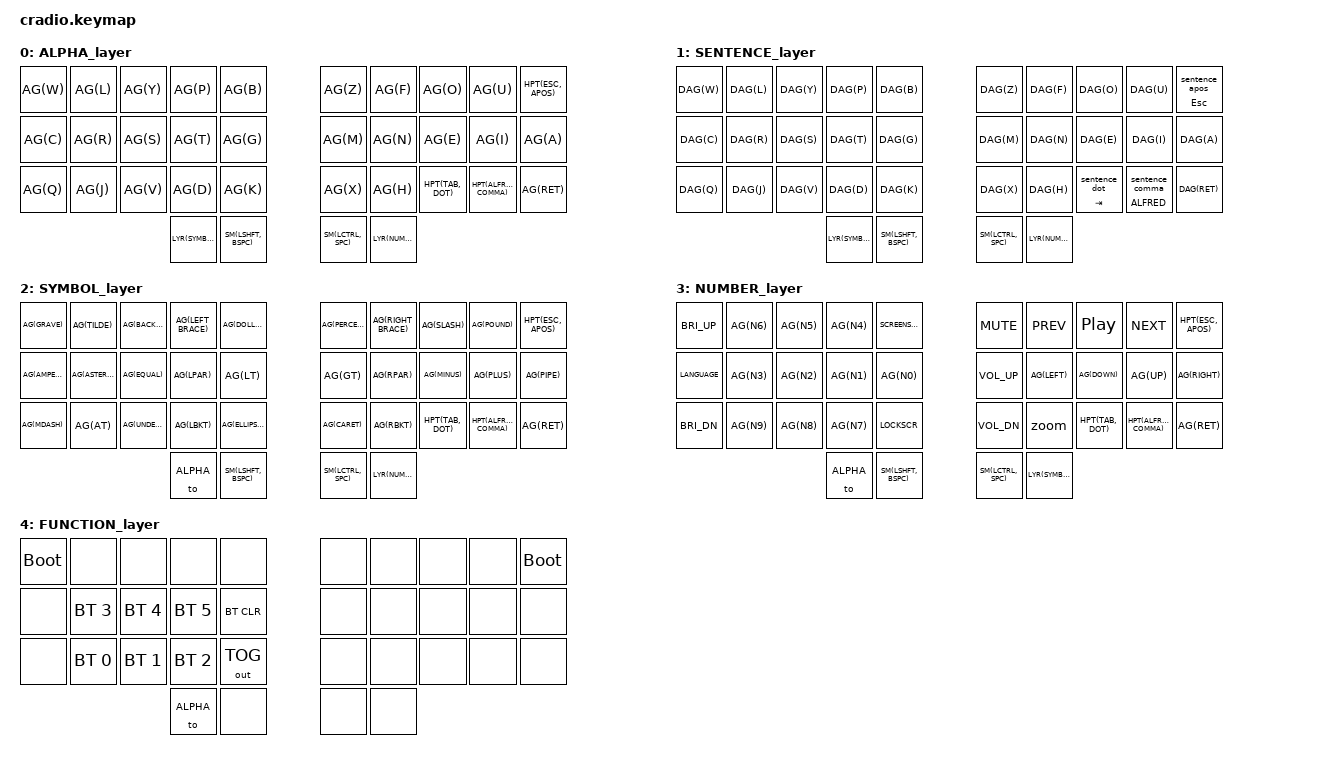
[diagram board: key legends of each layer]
/*
 * Copyright (c) 2020 The ZMK Contributors
 *
 * SPDX-License-Identifier: MIT
 */

#include <behaviors.dtsi>
#include <dt-bindings/zmk/keys.h>
#include <dt-bindings/zmk/bt.h>
#include <dt-bindings/zmk/outputs.h>

#define ALPHA 0
#define SENTENCE 1
#define SYMBOL 2
#define NUMBER 3
#define FUNCTION 4

#include "chords.keymap"

#define LANGUAGE LS(F1)
#define SCREENSHOT LG(LS(N4))
#define LOCKSCR LG(LC(Q))
#define ALFRED LG(SPC)
#define MDASH LA(LS(MINUS))
#define ELLIPSIS LA(SEMICOLON)

#define PHT(key1, key2) &prefer_hold_tap key1 key2
#define HPT(key1, key2) &hold_prefer_tap key1 key2
#define HTB(key1, key2) &balanced_hold_tap key1 key2
/ {
    behaviors {
        hold_prefer_tap: hold_prefer_tap {
            compatible = "zmk,behavior-hold-tap";
            label = "HOLD_PREFER_TAP";
            #binding-cells = <2>;
            tapping_term_ms = <200>;
            quick_tap_ms = <0>;
            flavor = "tap-preferred";
            bindings = <&kp>, <&kp>;
        };
        prefer_hold_tap: prefer_hold_tap {
            compatible = "zmk,behavior-hold-tap";
            label = "PREFER_HOLD_TAP";
            #binding-cells = <2>;
            tapping_term_ms = <200>;
            quick_tap_ms = <0>;
            flavor = "hold-preferred";
            bindings = <&kp>, <&kp>;
        };
        balanced_hold_tap: balanced_hold_tap {
            compatible = "zmk,behavior-hold-tap";
            label = "BALANCED_HOLD_TAP";
            #binding-cells = <2>;
            tapping_term_ms = <200>;
            quick_tap_ms = <0>;
            flavor = "balanced";
            bindings = <&kp>, <&kp>;
        };
    };
};

// Sticky mod on hold
#define SM(mod, keycode) &sm mod keycode
&sk {
    release-after-ms = <2000>;
    quick-release;
};
/ {
    behaviors {
        sm: sticky_mod {
            compatible = "zmk,behavior-hold-tap";
            label = "STICKY_MOD";
            #binding-cells = <2>;
            tapping_term_ms = <200>;
            quick_tap_ms = <0>;
            flavor = "hold-preferred";
            bindings = <&sk>, <&kp>;
        };
    };
};

// Like autoshift but for gui instead
#define AG(keycode) HPT(LG(keycode), keycode)

// Same, but dismisses sentence mode
#define str(s) #s
#define DISMISS_MACRO(key)                 \
macros {                                   \
  sentence_##key: sentence_##key {         \
    label = str(sentence_##key);           \
    compatible = "zmk,behavior-macro";     \
    #binding-cells = <0>;                  \
    tap-ms = <1>;                          \
    wait-ms = <1>;                         \
    bindings = <&to ALPHA &kp key>;        \
  };                                       \
  lg_sentence_##key: lg_sentence_##key {   \
    label = str(lg_sentence_##key);        \
    compatible = "zmk,behavior-macro";     \
    #binding-cells = <0>;                  \
    tap-ms = <1>;                          \
    wait-ms = <1>;                         \
    bindings = <&to ALPHA &kp LG(key)>;    \
  };                                       \
};                                         \
behaviors {                                \
  hold_prefer_##key: hold_prefer_##key {   \
    compatible = "zmk,behavior-hold-tap";  \
    label = str(hold_prefer_##key);        \
    #binding-cells = <2>;                  \
    tapping_term_ms = <200>;               \
    quick_tap_ms = <0>;                    \
    flavor = "tap-preferred";              \
    bindings = <&lg_sentence_##key>, <&sentence_##key>;  \
  };                                       \
};
/ {
  DISMISS_MACRO(A)
  DISMISS_MACRO(B)
  DISMISS_MACRO(C)
  DISMISS_MACRO(D)
  DISMISS_MACRO(E)
  DISMISS_MACRO(F)
  DISMISS_MACRO(G)
  DISMISS_MACRO(H)
  DISMISS_MACRO(I)
  DISMISS_MACRO(J)
  DISMISS_MACRO(K)
  DISMISS_MACRO(L)
  DISMISS_MACRO(M)
  DISMISS_MACRO(N)
  DISMISS_MACRO(O)
  DISMISS_MACRO(P)
  DISMISS_MACRO(Q)
  DISMISS_MACRO(R)
  DISMISS_MACRO(S)
  DISMISS_MACRO(T)
  DISMISS_MACRO(U)
  DISMISS_MACRO(V)
  DISMISS_MACRO(W)
  DISMISS_MACRO(X)
  DISMISS_MACRO(Y)
  DISMISS_MACRO(Z)
  DISMISS_MACRO(RET)
};
#define DAG(keycode) &hold_prefer_##keycode 0 0
/ {
  macros {
    sentence_dot: sentence_dot {
      label = "sentence_dot";
      compatible = "zmk,behavior-macro";
      #binding-cells = <0>;
      tap-ms = <1>;
      wait-ms = <1>;
      bindings = <&kp BSPC &kp DOT &kp SPC &sk LSHFT>;
    };
    sentence_comma: sentence_comma {
      label = "sentence_comma";
      compatible = "zmk,behavior-macro";
      #binding-cells = <0>;
      tap-ms = <1>;
      wait-ms = <1>;
      bindings = <&kp BSPC &kp COMMA &kp SPC>;
    };
    sentence_apos: sentence_apos {
      label = "sentence_apos";
      compatible = "zmk,behavior-macro";
      #binding-cells = <0>;
      tap-ms = <1>;
      wait-ms = <1>;
      bindings = <&kp BSPC &kp APOS>;
    };
  };
  behaviors {
    hold_prefer_dot: hold_prefer_dot {
      compatible = "zmk,behavior-hold-tap";
      label = "hold_prefer_dot";
      #binding-cells = <2>;
      tapping_term_ms = <200>;
      quick_tap_ms = <0>;
      flavor = "tap-preferred";
      bindings = <&kp>, <&sentence_dot>;
    };
    hold_prefer_comma: hold_prefer_comma {
      compatible = "zmk,behavior-hold-tap";
      label = "hold_prefer_comma";
      #binding-cells = <2>;
      tapping_term_ms = <200>;
      quick_tap_ms = <0>;
      flavor = "tap-preferred";
      bindings = <&kp>, <&sentence_comma>;
    };
    hold_prefer_apos: hold_prefer_apos {
      compatible = "zmk,behavior-hold-tap";
      label = "hold_prefer_apos";
      #binding-cells = <2>;
      tapping_term_ms = <200>;
      quick_tap_ms = <0>;
      flavor = "tap-preferred";
      bindings = <&kp>, <&sentence_apos>;
    };
  };
};

// chord spc + bkspc to delete a word, or hold for a hyper sticky modifier
#define HYPER LG(LA(LCTRL))
/ {
  combos {
    compatible = "zmk,combos";
    combo_del_word {
      timeout-ms = <60>;
      bindings = <SM(HYPER, LA(BSPC))>;
      key-positions = <31 32>;
    };
  };
};

// Chord left thumb keys as left click, right thumb keys as right click
// Hold for command versions
// TODO https://github.com/zmkfirmware/zmk/pull/1430
/ {
  combos {
    compatible = "zmk,combos";
    combo_left_click {
      timeout-ms = <60>;
      bindings = <HPT(&none, &none)>;
      key-positions = <30 31>;
    };
    combo_right_click {
      timeout-ms = <60>;
      bindings = <HPT(&none, &none)>;
      key-positions = <32 33>;
    };
  };
};

// Tap to toggle layer, chord to momentarily switch
#define LYR(layer) &mo_tog layer layer
/ {
  behaviors {
    mo_tog: behavior_mo_tog {
      compatible = "zmk,behavior-hold-tap";
      label = "mo_tog";
      #binding-cells = <2>;
      flavor = "hold-preferred";
      tapping-term-ms = <200>;
      bindings = <&mo>, <&tog>;
    };
  };
};

// Chord SYMBOL + NUMBER to get to FUNCTION layer
&sl {
    release-after-ms = <10000>;
};
/ {
  combos {
    compatible = "zmk,combos";
    combo_function_layer {
      timeout-ms = <60>;
      bindings = <&sl FUNCTION>;
      key-positions = <30 33>;
    };
  };
};

// Zoom in and out
/ {
  behaviors {
    zoom: zoom {
      compatible = "zmk,behavior-mod-morph";
      label = "ZOOM";
      #binding-cells = <0>;
      bindings = <&kp LG(PLUS)>, <&kp LG(MINUS)>;
      mods = <(MOD_LSFT|MOD_RSFT)>;
    };
  };
};

/ {
  keymap {
    compatible = "zmk,keymap";

    ALPHA_layer {
      bindings = <
        AG(W)  AG(L)  AG(Y)  AG(P)  AG(B)    AG(Z)  AG(F)  AG(O)          AG(U)               HPT(ESC, APOS)
        AG(C)  AG(R)  AG(S)  AG(T)  AG(G)    AG(M)  AG(N)  AG(E)          AG(I)               AG(A)
        AG(Q)  AG(J)  AG(V)  AG(D)  AG(K)    AG(X)  AG(H)  HPT(TAB, DOT)  HPT(ALFRED, COMMA)  AG(RET)
             LYR(SYMBOL)  SM(LSHFT, BSPC)    SM(LCTRL, SPC)  LYR(NUMBER)
      >;
    };

    SENTENCE_layer {
      bindings = <
        DAG(W)  DAG(L)  DAG(Y)  DAG(P)  DAG(B)    DAG(Z)  DAG(F)  DAG(O)                  DAG(U)                        &hold_prefer_apos ESC 0
        DAG(C)  DAG(R)  DAG(S)  DAG(T)  DAG(G)    DAG(M)  DAG(N)  DAG(E)                  DAG(I)                        DAG(A)
        DAG(Q)  DAG(J)  DAG(V)  DAG(D)  DAG(K)    DAG(X)  DAG(H)  &hold_prefer_dot TAB 0  &hold_prefer_comma ALFRED 0   DAG(RET)
                  LYR(SYMBOL)  SM(LSHFT, BSPC)    SM(LCTRL, SPC)  LYR(NUMBER)
      >;
    };

    SYMBOL_layer {
      bindings = <
        AG(GRAVE)      AG(TILDE)     AG(BACKSLASH)   AG(LEFT_BRACE)  AG(DOLLAR)      AG(PERCENT)  AG(RIGHT_BRACE)  AG(SLASH)      AG(POUND)           HPT(ESC, APOS)
        AG(AMPERSAND)  AG(ASTERISK)  AG(EQUAL)       AG(LPAR)        AG(LT)          AG(GT)       AG(RPAR)         AG(MINUS)      AG(PLUS)            AG(PIPE)
        AG(MDASH)      AG(AT)        AG(UNDERSCORE)  AG(LBKT)        AG(ELLIPSIS)    AG(CARET)    AG(RBKT)         HPT(TAB, DOT)  HPT(ALFRED, COMMA)  AG(RET)
                                                       &to ALPHA  SM(LSHFT, BSPC)    SM(LCTRL, SPC)  LYR(NUMBER)
      >;
    };

    NUMBER_layer {
      bindings = <
        &kp C_BRI_UP  AG(N6)  AG(N5)  AG(N4)  &kp SCREENSHOT    &kp C_MUTE    &kp C_PREV  &kp C_PP       &kp C_NEXT          HPT(ESC, APOS)
        &kp LANGUAGE  AG(N3)  AG(N2)  AG(N1)  AG(N0)            &kp C_VOL_UP  AG(LEFT)    AG(DOWN)       AG(UP)              AG(RIGHT)
        &kp C_BRI_DN  AG(N9)  AG(N8)  AG(N7)  &kp LOCKSCR       &kp C_VOL_DN  &zoom       HPT(TAB, DOT)  HPT(ALFRED, COMMA)  AG(RET)
                                  &to ALPHA  SM(LSHFT, BSPC)    SM(LCTRL, SPC)  LYR(SYMBOL)
      >;
    };

    FUNCTION_layer {
      bindings = <
        &bootloader  &none         &none         &none         &none           &none  &none  &none  &none  &bootloader
        &none        &bt BT_SEL 3  &bt BT_SEL 4  &bt BT_SEL 5  &bt BT_CLR      &none  &none  &none  &none  &none
        &none        &bt BT_SEL 0  &bt BT_SEL 1  &bt BT_SEL 2  &out OUT_TOG    &none  &none  &none  &none  &none
                                                         &to ALPHA  &none      &none  &none
      >;
    };
  };
};
